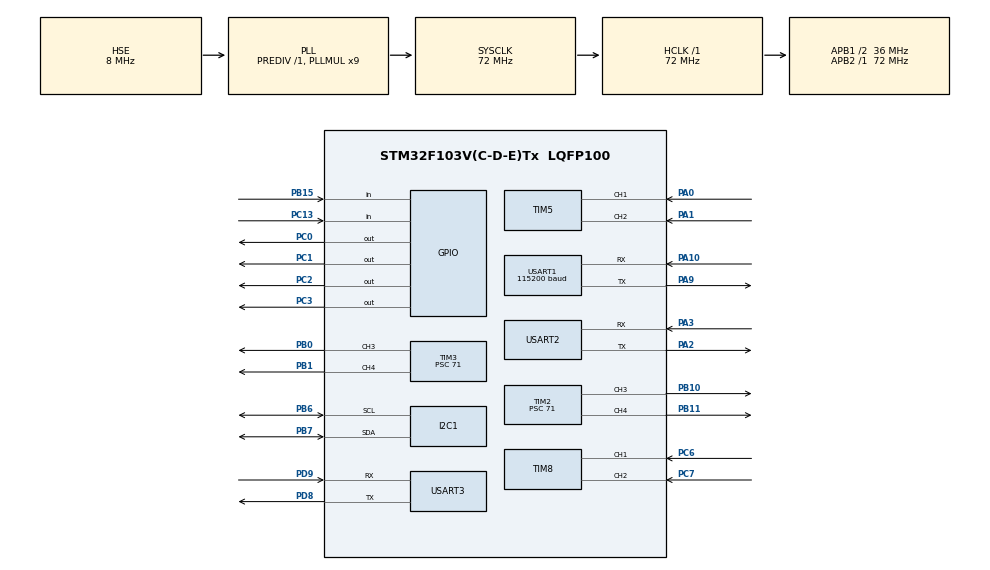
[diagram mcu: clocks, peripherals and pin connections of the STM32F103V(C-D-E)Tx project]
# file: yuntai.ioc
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I2C1.I2C_Mode=I2C_Fast
Mcu.Family=STM32F1
Mcu.Name=STM32F103V(C-D-E)Tx
Mcu.Package=LQFP100
NVIC.PriorityGroup=NVIC_PRIORITYGROUP_4
NVIC.TIM8_UP_IRQn=true\:0\:0\:false\:false\:true\:true\:true
NVIC.USART1_IRQn=true\:1\:0\:true\:false\:true\:true\:true
NVIC.USART2_IRQn=true\:3\:0\:true\:false\:true\:true\:true
NVIC.USART3_IRQn=true\:2\:0\:true\:false\:true\:true\:true
OSC_IN.Mode=HSE-External-Oscillator
OSC_IN.Signal=RCC_OSC_IN
OSC_OUT.Mode=HSE-External-Oscillator
OSC_OUT.Signal=RCC_OSC_OUT
PA0-WKUP.Signal=S_TIM5_CH1
PA1.Signal=S_TIM5_CH2
PA10.Mode=Asynchronous
PA10.Signal=USART1_RX
PA13.Mode=Serial_Wire
PA13.Signal=SYS_JTMS-SWDIO
PA14.Mode=Serial_Wire
PA14.Signal=SYS_JTCK-SWCLK
PA2.Mode=Asynchronous
PA2.Signal=USART2_TX
PA3.Mode=Asynchronous
PA3.Signal=USART2_RX
PA9.Mode=Asynchronous
PA9.Signal=USART1_TX
PB0.Signal=S_TIM3_CH3
PB1.Signal=S_TIM3_CH4
PB10.Signal=S_TIM2_CH3
PB11.Signal=S_TIM2_CH4
PB15.GPIO_PuPd=GPIO_PULLUP
PB15.Signal=GPIO_Input
PB6.Mode=I2C
PB6.Signal=I2C1_SCL
PB7.Mode=I2C
PB7.Signal=I2C1_SDA
PC0.PinState=GPIO_PIN_SET
PC0.Signal=GPIO_Output
PC1.Signal=GPIO_Output
PC13-TAMPER-RTC.GPIO_PuPd=GPIO_PULLDOWN
PC13-TAMPER-RTC.Signal=GPIO_Input
PC2.Signal=GPIO_Output
PC3.PinState=GPIO_PIN_SET
PC3.Signal=GPIO_Output
PC6.Signal=S_TIM8_CH1
PC7.Signal=S_TIM8_CH2
PD8.Mode=Asynchronous
PD8.Signal=USART3_TX
PD9.Mode=Asynchronous
PD9.Signal=USART3_RX
ProjectManager.HeapSize=0x200
ProjectManager.StackSize=0x400
ProjectManager.TargetToolchain=MDK-ARM V5
RCC.AHBFreq_Value=72000000
RCC.APB1CLKDivider=RCC_HCLK_DIV2
RCC.APB1Freq_Value=36000000
RCC.APB1TimFreq_Value=72000000
RCC.APB2Freq_Value=72000000
RCC.APB2TimFreq_Value=72000000
RCC.HCLKFreq_Value=72000000
RCC.PLLMUL=RCC_PLL_MUL9
RCC.PLLSourceVirtual=RCC_PLLSOURCE_HSE
RCC.SYSCLKFreq_VALUE=72000000
RCC.SYSCLKSource=RCC_SYSCLKSOURCE_PLLCLK
RCC.USBFreq_Value=72000000
SH.S_TIM2_CH3.0=TIM2_CH3,PWM Generation3 CH3
SH.S_TIM2_CH4.0=TIM2_CH4,PWM Generation4 CH4
SH.S_TIM3_CH3.0=TIM3_CH3,PWM Generation3 CH3
SH.S_TIM3_CH4.0=TIM3_CH4,PWM Generation4 CH4
SH.S_TIM5_CH1.0=TIM5_CH1,Encoder_Interface
SH.S_TIM5_CH2.0=TIM5_CH2,Encoder_Interface
SH.S_TIM8_CH1.0=TIM8_CH1,Encoder_Interface
SH.S_TIM8_CH2.0=TIM8_CH2,Encoder_Interface
TIM2.AutoReloadPreload=TIM_AUTORELOAD_PRELOAD_ENABLE
TIM2.Channel-PWM\ Generation3\ CH3=TIM_CHANNEL_3
TIM2.Channel-PWM\ Generation4\ CH4=TIM_CHANNEL_4
TIM2.Period=19999
TIM2.Prescaler=71
TIM2.Pulse-PWM\ Generation3\ CH3=1500
TIM2.Pulse-PWM\ Generation4\ CH4=1500
TIM3.AutoReloadPreload=TIM_AUTORELOAD_PRELOAD_ENABLE
TIM3.Channel-PWM\ Generation3\ CH3=TIM_CHANNEL_3
TIM3.Channel-PWM\ Generation4\ CH4=TIM_CHANNEL_4
TIM3.Period=999
TIM3.Prescaler=71
TIM5.EncoderMode=TIM_ENCODERMODE_TI12
TIM8.EncoderMode=TIM_ENCODERMODE_TI12
USART1.BaudRate=115200
USART1.VirtualMode=VM_ASYNC
USART2.VirtualMode=VM_ASYNC
USART3.VirtualMode=VM_ASYNC
VP_TIM2_VS_ClockSourceINT.Mode=Internal
VP_TIM3_VS_ClockSourceINT.Mode=Internal
board=custom

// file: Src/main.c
/* USER CODE BEGIN Header */
/**
  ******************************************************************************
  * @file           : main.c
  * @brief          : Main program body
  ******************************************************************************
  * @attention
  *
  * <h2><center>&copy; Copyright (c) 2023 STMicroelectronics.
  * All rights reserved.</center></h2>
  *
  * This software component is licensed by ST under BSD 3-Clause license,
  * the "License"; You may not use this file except in compliance with the
  * License. You may obtain a copy of the License at:
  *                        opensource.org/licenses/BSD-3-Clause
  *
  ******************************************************************************
  */
/* USER CODE END Header */
#include "main.h"
#include "i2c.h"
#include "tim.h"
#include "usart.h"
#include "gpio.h"

/* USER CODE BEGIN Includes */
#include "bsp_uasrt.h"
#include "jy901.h"
#include "oled.h"
#include "work.h"
/* USER CODE END Includes */

void SystemClock_Config(void);

int main(void)
{

  /* MCU Configuration--------------------------------------------------------*/

  /* Reset of all peripherals, Initializes the Flash interface and the Systick. */
  HAL_Init();

  /* Configure the system clock */
  SystemClock_Config();

  /* Initialize all configured peripherals */
  MX_GPIO_Init();
  MX_TIM2_Init();
  MX_TIM3_Init();
  MX_TIM5_Init();
  MX_TIM8_Init();
  MX_USART1_UART_Init();
  MX_USART2_UART_Init();
  MX_USART3_UART_Init();
  MX_I2C1_Init();
  /* USER CODE BEGIN 2 */

//	HAL_TIM_Encoder_Start(&htim5, TIM_CHANNEL_ALL);//开启TIM5的编码器接口模式 左上电机
//	HAL_TIM_Encoder_Start(&htim8, TIM_CHANNEL_ALL);
//
//	HAL_TIM_PWM_Start(&htim3,TIM_CHANNEL_3);//开启TIM3_CH3的PWM输出
//	HAL_GPIO_WritePin(GPIOC,GPIO_PIN_0,GPIO_PIN_SET);//初始化BIN1引脚为低电平
//	HAL_GPIO_WritePin(GPIOC,GPIO_PIN_1,GPIO_PIN_RESET);//初始化BIN2引脚为高电平
//
//
//	HAL_TIM_PWM_Start(&htim3,TIM_CHANNEL_4);//开启TIM3_CH4的PWM输出
//	HAL_GPIO_WritePin(GPIOC,GPIO_PIN_3,GPIO_PIN_SET);//初始化BIN1引脚为低电平
//	HAL_GPIO_WritePin(GPIOC,GPIO_PIN_2,GPIO_PIN_RESET);
//

	HAL_TIM_PWM_Start(&htim2,TIM_CHANNEL_3);//舵机上 上正
	HAL_TIM_PWM_Start(&htim2,TIM_CHANNEL_4);//舵机下	 左正右负
	 __HAL_TIM_SET_COMPARE(&htim2, TIM_CHANNEL_4, 1500);
	 __HAL_TIM_SET_COMPARE(&htim2, TIM_CHANNEL_3, 1500);
//	HAL_TIM_Encoder_Start(&htim5, TIM_CHANNEL_ALL);//开启TIM5的编码器接口模式 左上电机
//	HAL_TIM_Encoder_Start(&htim8, TIM_CHANNEL_ALL);//开启TIM8的编码器接口模式 右上电机

  User_USART_Init(&JY901_data);
//  HAL_UART_Receive_IT(&huart1,&uart1_rxbuff,1);
//	HAL_UART_Receive_IT(&huart2,JY901_data.RxBuffer,RXBUFFER_LEN);
  HAL_UART_Receive_IT(&huart3,&uart3_rxbuff,1);

	OLED_Display_On();

	OLED_Init();
  OLED_Clear();

  /* USER CODE END 2 */

  /* Infinite loop */
  while (1)
  {

    /* USER CODE BEGIN 3 */

		Lcd_Proc();

  }
  /* USER CODE END 3 */
}

void SystemClock_Config(void)
{
  RCC_OscInitTypeDef RCC_OscInitStruct = {0};
  RCC_ClkInitTypeDef RCC_ClkInitStruct = {0};

  /** Initializes the RCC Oscillators according to the specified parameters
  * in the RCC_OscInitTypeDef structure.
  */
  RCC_OscInitStruct.OscillatorType = RCC_OSCILLATORTYPE_HSE;
  RCC_OscInitStruct.HSEState = RCC_HSE_ON;
  RCC_OscInitStruct.HSEPredivValue = RCC_HSE_PREDIV_DIV1;
  RCC_OscInitStruct.HSIState = RCC_HSI_ON;
  RCC_OscInitStruct.PLL.PLLState = RCC_PLL_ON;
  RCC_OscInitStruct.PLL.PLLSource = RCC_PLLSOURCE_HSE;
  RCC_OscInitStruct.PLL.PLLMUL = RCC_PLL_MUL9;
  if (HAL_RCC_OscConfig(&RCC_OscInitStruct) != HAL_OK)
  {
    Error_Handler();
  }
  /** Initializes the CPU, AHB and APB buses clocks
  */
  RCC_ClkInitStruct.ClockType = RCC_CLOCKTYPE_HCLK|RCC_CLOCKTYPE_SYSCLK
                              |RCC_CLOCKTYPE_PCLK1|RCC_CLOCKTYPE_PCLK2;
  RCC_ClkInitStruct.SYSCLKSource = RCC_SYSCLKSOURCE_PLLCLK;
  RCC_ClkInitStruct.AHBCLKDivider = RCC_SYSCLK_DIV1;
  RCC_ClkInitStruct.APB1CLKDivider = RCC_HCLK_DIV2;
  RCC_ClkInitStruct.APB2CLKDivider = RCC_HCLK_DIV1;

  if (HAL_RCC_ClockConfig(&RCC_ClkInitStruct, FLASH_LATENCY_2) != HAL_OK)
  {
    Error_Handler();
  }
}

void Error_Handler(void)
{
  __disable_irq();
  while (1)
  {
  }
}

/************************ (C) COPYRIGHT STMicroelectronics *****END OF FILE****/
